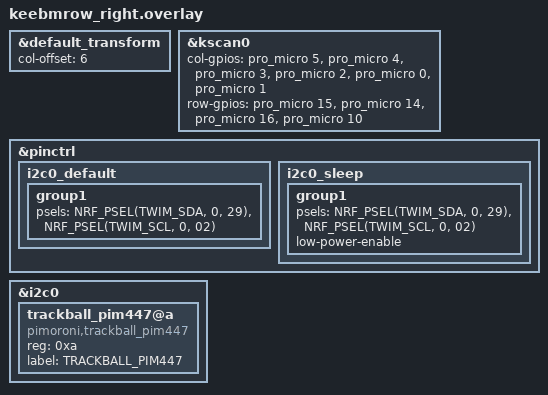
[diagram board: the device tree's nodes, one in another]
/*
 * Copyright (c) 2020 Pete Johanson
 *
 * SPDX-License-Identifier: MIT
 */

#include "keebmrow.dtsi"

&default_transform {
    col-offset = <6>;
};

// &five_column_transform {
//     col-offset = <6>;
// };

&kscan0 {

    col-gpios
        = <&pro_micro 5 (GPIO_ACTIVE_HIGH)>
        , <&pro_micro 4 (GPIO_ACTIVE_HIGH)>
        , <&pro_micro 3 (GPIO_ACTIVE_HIGH)>
        , <&pro_micro 2 (GPIO_ACTIVE_HIGH)>
        , <&pro_micro 0 (GPIO_ACTIVE_HIGH)>
        , <&pro_micro 1 (GPIO_ACTIVE_HIGH)>
        ;
        row-gpios
            = <&pro_micro 15 (GPIO_ACTIVE_HIGH | GPIO_PULL_DOWN)>
            , <&pro_micro 14 (GPIO_ACTIVE_HIGH | GPIO_PULL_DOWN)>
            , <&pro_micro 16 (GPIO_ACTIVE_HIGH | GPIO_PULL_DOWN)>
            , <&pro_micro 10 (GPIO_ACTIVE_HIGH | GPIO_PULL_DOWN)>
            ;
};


&pinctrl {
    i2c0_default: i2c0_default {
        group1 {
            psels = <NRF_PSEL(TWIM_SDA, 0, 29)>,
                <NRF_PSEL(TWIM_SCL, 0, 02)>;
        };
    };

    i2c0_sleep: i2c0_sleep {
        group1 {
            psels = <NRF_PSEL(TWIM_SDA, 0, 29)>,
                <NRF_PSEL(TWIM_SCL, 0, 02)>;
            low-power-enable;
        };
    };
};

&i2c0 {
    status = "okay";
    trackball_pim447@a {
        compatible = "pimoroni,trackball_pim447";
        reg = <0xa>;
        label = "TRACKBALL_PIM447";
    };
};
